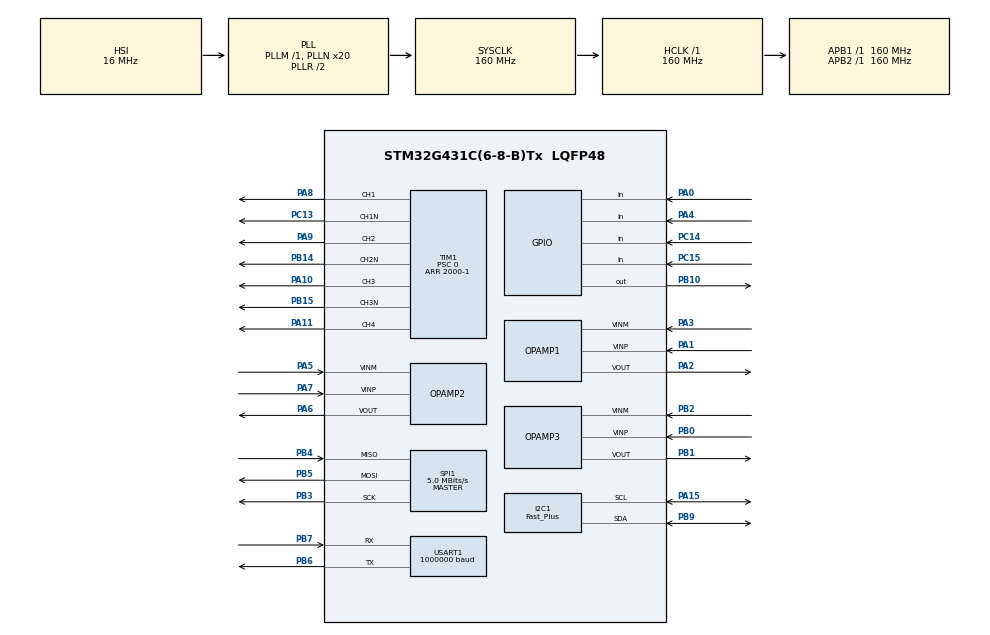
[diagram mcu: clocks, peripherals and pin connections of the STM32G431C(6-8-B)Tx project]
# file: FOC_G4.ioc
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ADC1.ContinuousConvMode=ENABLE
ADC1.DataAlign=ADC_DATAALIGN_RIGHT
ADC1.EOCSelection=ADC_EOC_SINGLE_CONV
ADC1.EnableAnalogWatchDog1=false
ADC1.EnableInjectedConversion=ENABLE
ADC1.EnableInjectedOversampling=DISABLE
ADC1.EnableRegularConversion=DISABLE
ADC1.ExternalTrigInjecConv=ADC_EXTERNALTRIGINJEC_T1_CC4
ADC1.ExternalTrigInjecConvEdge=ADC_EXTERNALTRIGINJECCONV_EDGE_FALLING
ADC1.InjNumberOfConversion=2
ADC1.InjectedChannel-11\#ChannelInjectedConversion=ADC_CHANNEL_3
ADC1.InjectedChannel-5\#ChannelInjectedConversion=ADC_CHANNEL_12
ADC1.InjectedConvMode=None
ADC1.InjectedOffsetNumber-11\#ChannelInjectedConversion=ADC_OFFSET_NONE
ADC1.InjectedOffsetNumber-5\#ChannelInjectedConversion=ADC_OFFSET_NONE
ADC1.InjectedOffsetSaturation-5\#ChannelInjectedConversion=DISABLE
ADC1.InjectedOffsetSign-5\#ChannelInjectedConversion=ADC_OFFSET_SIGN_POSITIVE
ADC1.InjectedRank-11\#ChannelInjectedConversion=2
ADC1.InjectedRank-5\#ChannelInjectedConversion=1
ADC1.InjectedSamplingTime-11\#ChannelInjectedConversion=ADC_SAMPLETIME_2CYCLES_5
ADC1.InjectedSamplingTime-5\#ChannelInjectedConversion=ADC_SAMPLETIME_2CYCLES_5
ADC1.Mode=ADC_MODE_INDEPENDENT
ADC1.Overrun=ADC_OVR_DATA_PRESERVED
ADC1.Rank2_Channel=ADC_CHANNEL_3
ADC1.Resolution=ADC_RESOLUTION_12B
ADC1.injectedQueueMode=DISABLE
ADC1.master=1
ADC2.ContinuousConvMode=ENABLE
ADC2.EOCSelection=ADC_EOC_SINGLE_CONV
ADC2.EnableInjectedConversion=ENABLE
ADC2.EnableInjectedOversampling=DISABLE
ADC2.EnableRegularConversion=DISABLE
ADC2.ExternalTrigInjecConv=ADC_EXTERNALTRIGINJEC_T1_CC4
ADC2.ExternalTrigInjecConvEdge=ADC_EXTERNALTRIGINJECCONV_EDGE_FALLING
ADC2.InjNumberOfConversion=1
ADC2.InjectedChannel-11\#ChannelInjectedConversion=ADC_CHANNEL_3
ADC2.InjectedConvMode=None
ADC2.InjectedOffsetNumber-11\#ChannelInjectedConversion=ADC_OFFSET_NONE
ADC2.InjectedRank-11\#ChannelInjectedConversion=1
ADC2.InjectedSamplingTime-11\#ChannelInjectedConversion=ADC_SAMPLETIME_2CYCLES_5
ADC2.injectedQueueMode=DISABLE
Dma.Request0=USART1_RX
Dma.Request1=USART1_TX
Dma.USART1_RX.0.Direction=DMA_PERIPH_TO_MEMORY
Dma.USART1_RX.0.EventEnable=DISABLE
Dma.USART1_RX.0.Instance=DMA2_Channel6
Dma.USART1_RX.0.MemDataAlignment=DMA_MDATAALIGN_BYTE
Dma.USART1_RX.0.MemInc=DMA_MINC_ENABLE
Dma.USART1_RX.0.Mode=DMA_NORMAL
Dma.USART1_RX.0.PeriphDataAlignment=DMA_PDATAALIGN_BYTE
Dma.USART1_RX.0.PeriphInc=DMA_PINC_DISABLE
Dma.USART1_RX.0.Polarity=HAL_DMAMUX_REQ_GEN_RISING
Dma.USART1_RX.0.Priority=DMA_PRIORITY_MEDIUM
Dma.USART1_RX.0.RequestNumber=1
Dma.USART1_RX.0.SignalID=NONE
Dma.USART1_RX.0.SyncEnable=DISABLE
Dma.USART1_RX.0.SyncPolarity=HAL_DMAMUX_SYNC_NO_EVENT
Dma.USART1_RX.0.SyncRequestNumber=1
Dma.USART1_RX.0.SyncSignalID=NONE
Dma.USART1_TX.1.Direction=DMA_MEMORY_TO_PERIPH
Dma.USART1_TX.1.EventEnable=DISABLE
Dma.USART1_TX.1.Instance=DMA1_Channel4
Dma.USART1_TX.1.MemDataAlignment=DMA_MDATAALIGN_BYTE
Dma.USART1_TX.1.MemInc=DMA_MINC_ENABLE
Dma.USART1_TX.1.Mode=DMA_NORMAL
Dma.USART1_TX.1.PeriphDataAlignment=DMA_PDATAALIGN_BYTE
Dma.USART1_TX.1.PeriphInc=DMA_PINC_DISABLE
Dma.USART1_TX.1.Polarity=HAL_DMAMUX_REQ_GEN_RISING
Dma.USART1_TX.1.Priority=DMA_PRIORITY_MEDIUM
Dma.USART1_TX.1.RequestNumber=1
Dma.USART1_TX.1.SignalID=NONE
Dma.USART1_TX.1.SyncEnable=DISABLE
Dma.USART1_TX.1.SyncPolarity=HAL_DMAMUX_SYNC_NO_EVENT
Dma.USART1_TX.1.SyncRequestNumber=1
Dma.USART1_TX.1.SyncSignalID=NONE
I2C1.Analog_Filter=I2C_ANALOGFILTER_ENABLE
I2C1.CustomTiming=Disabled
I2C1.I2C_Fall_Time=50
I2C1.I2C_Rise_Time=50
I2C1.I2C_Speed_Mode=I2C_Fast_Plus
I2C1.Timing=0x00F01F5B
Mcu.Family=STM32G4
Mcu.Name=STM32G431C(6-8-B)Tx
Mcu.Package=LQFP48
NVIC.ADC1_2_IRQn=true\:0\:0\:true\:false\:true\:false\:true\:true\:true
NVIC.DMA1_Channel4_IRQn=true\:0\:0\:false\:false\:true\:false\:true\:true\:true
NVIC.DMA2_Channel6_IRQn=true\:0\:0\:false\:false\:true\:false\:true\:true\:true
NVIC.PriorityGroup=NVIC_PRIORITYGROUP_4
NVIC.TIM1_UP_TIM16_IRQn=true\:15\:0\:true\:false\:true\:false\:false\:true\:true
NVIC.TIM4_IRQn=true\:15\:0\:false\:false\:true\:false\:false\:true\:true
NVIC.TimeBase=TIM4_IRQn
NVIC.TimeBaseIP=TIM4
NVIC.USART1_IRQn=true\:1\:0\:true\:false\:true\:false\:true\:true\:true
OPAMP1.PowerMode=OPAMP_POWERMODE_NORMALSPEED
OPAMP2.PowerMode=OPAMP_POWERMODE_NORMALSPEED
OPAMP3.PowerMode=OPAMP_POWERMODE_NORMALSPEED
PA0.Signal=GPIO_Input
PA1.Mode=Standalone
PA1.Signal=OPAMP1_VINP
PA10.GPIO_PuPd=GPIO_PULLDOWN
PA10.GPIO_Speed=GPIO_SPEED_FREQ_VERY_HIGH
PA10.Signal=S_TIM1_CH3
PA11.Signal=S_TIM1_CH4
PA13.Mode=Serial_Wire
PA13.Signal=SYS_JTMS-SWDIO
PA14.Mode=Serial_Wire
PA14.Signal=SYS_JTCK-SWCLK
PA15.GPIO_Pu=GPIO_PULLUP
PA15.GPIO_Speed=GPIO_SPEED_FREQ_VERY_HIGH
PA15.Mode=I2C
PA15.Signal=I2C1_SCL
PA2.GPIO_Mode=GPIO_MODE_ANALOG
PA2.GPIO_PuPd=GPIO_NOPULL
PA2.Signal=SharedAnalog_PA2
PA3.Mode=Standalone
PA3.Signal=OPAMP1_VINM
PA4.Signal=GPIO_Input
PA5.Mode=Standalone
PA5.Signal=OPAMP2_VINM
PA6.GPIO_Mode=GPIO_MODE_ANALOG
PA6.Signal=SharedAnalog_PA6
PA7.Mode=Standalone
PA7.Signal=OPAMP2_VINP
PA8.GPIO_PuPd=GPIO_PULLDOWN
PA8.GPIO_Speed=GPIO_SPEED_FREQ_VERY_HIGH
PA8.Signal=S_TIM1_CH1
PA9.GPIO_PuPd=GPIO_PULLDOWN
PA9.GPIO_Speed=GPIO_SPEED_FREQ_VERY_HIGH
PA9.Signal=S_TIM1_CH2
PB0.Mode=Standalone
PB0.Signal=OPAMP3_VINP
PB1.GPIO_PuPd=GPIO_NOPULL
PB1.Signal=SharedAnalog_PB1
PB10.Signal=GPIO_Output
PB14.GPIO_PuPd=GPIO_PULLDOWN
PB14.GPIO_Speed=GPIO_SPEED_FREQ_VERY_HIGH
PB14.Mode=PWM Generation2 CH2 CH2N
PB14.Signal=TIM1_CH2N
PB15.GPIO_PuPd=GPIO_PULLDOWN
PB15.GPIO_Speed=GPIO_SPEED_FREQ_VERY_HIGH
PB15.Mode=PWM Generation3 CH3 CH3N
PB15.Signal=TIM1_CH3N
PB2.Mode=Standalone
PB2.Signal=OPAMP3_VINM
PB3.Mode=Full_Duplex_Master
PB3.Signal=SPI1_SCK
PB4.Mode=Full_Duplex_Master
PB4.Signal=SPI1_MISO
PB5.Mode=Full_Duplex_Master
PB5.Signal=SPI1_MOSI
PB6.Mode=Multiprocessor_communication
PB6.Signal=USART1_TX
PB7.Mode=Multiprocessor_communication
PB7.Signal=USART1_RX
PB9.GPIO_FM9=SYSCFG_FASTMODEPLUS_PB9
PB9.GPIO_Pu=GPIO_PULLUP
PB9.GPIO_Speed=GPIO_SPEED_FREQ_VERY_HIGH
PB9.Mode=I2C
PB9.Signal=I2C1_SDA
PC13.GPIO_PuPd=GPIO_PULLDOWN
PC13.GPIO_Speed=GPIO_SPEED_FREQ_LOW
PC13.Mode=PWM Generation1 CH1 CH1N
PC13.Signal=TIM1_CH1N
PC14-OSC32_IN.Signal=GPIO_Input
PC15-OSC32_OUT.Signal=GPIO_Input
PF0-OSC_IN.Mode=HSE-External-Oscillator
PF0-OSC_IN.Signal=RCC_OSC_IN
PF1-OSC_OUT.Mode=HSE-External-Oscillator
PF1-OSC_OUT.Signal=RCC_OSC_OUT
ProjectManager.HeapSize=0x200
ProjectManager.StackSize=0x400
ProjectManager.TargetToolchain=MDK-ARM V5.32
RCC.ADC12Freq_Value=160000000
RCC.AHBFreq_Value=160000000
RCC.APB1Freq_Value=160000000
RCC.APB1TimFreq_Value=160000000
RCC.APB2Freq_Value=160000000
RCC.APB2TimFreq_Value=160000000
RCC.CortexFreq_Value=160000000
RCC.EXTERNAL_CLOCK_VALUE=12288000
RCC.HCLKFreq_Value=160000000
RCC.HSE_VALUE=8000000
RCC.HSI48_VALUE=48000000
RCC.HSI_VALUE=16000000
RCC.LSE_VALUE=32768
RCC.PLLN=20
RCC.SYSCLKFreq_VALUE=160000000
RCC.SYSCLKSource=RCC_SYSCLKSOURCE_PLLCLK
RCC.USBFreq_Value=160000000
RCC.VCOOutputFreq_Value=320000000
RealThread.RT-Thread.3.1.3.RTAaThreadCcRTOSJjkernel=true
RealThread.RT-Thread.3.1.3.RT_MAIN_THREAD_STACK_SIZE=512
RealThread.RT-Thread.3.1.3.RT_TICK_PER_SECOND=10000
RealThread.RT-Thread.3.1.3.RT_USING_HEAP=1
RealThread.RT-Thread.3.1.3.RT_USING_MESSAGEQUEUE=1
SH.S_TIM1_CH1.0=TIM1_CH1,PWM Generation1 CH1 CH1N
SH.S_TIM1_CH2.0=TIM1_CH2,PWM Generation2 CH2 CH2N
SH.S_TIM1_CH3.0=TIM1_CH3,PWM Generation3 CH3 CH3N
SH.S_TIM1_CH4.0=TIM1_CH4,PWM Generation4 CH4
SH.SharedAnalog_PA2.0=OPAMP1_VOUT,Standalone
SH.SharedAnalog_PA2.1=ADC1_IN3,IN3-Single-Ended
SH.SharedAnalog_PA6.0=OPAMP2_VOUT,Standalone
SH.SharedAnalog_PA6.1=ADC2_IN3,IN3-Single-Ended
SH.SharedAnalog_PB1.0=OPAMP3_VOUT,Standalone
SH.SharedAnalog_PB1.1=ADC1_IN12,IN12-Single-Ended
SPI1.BaudRatePrescaler=SPI_BAUDRATEPRESCALER_32
SPI1.CalculateBaudRate=5.0 MBits/s
SPI1.Direction=SPI_DIRECTION_2LINES
SPI1.Mode=SPI_MODE_MASTER
SPI1.VirtualType=VM_MASTER
TIM1.AutoReloadPreload=TIM_AUTORELOAD_PRELOAD_ENABLE
TIM1.Channel-PWM\ Generation1\ CH1\ CH1N=TIM_CHANNEL_1
TIM1.Channel-PWM\ Generation2\ CH2\ CH2N=TIM_CHANNEL_2
TIM1.Channel-PWM\ Generation3\ CH3\ CH3N=TIM_CHANNEL_3
TIM1.Channel-PWM\ Generation4\ CH4=TIM_CHANNEL_4
TIM1.ClockDivision=TIM_CLOCKDIVISION_DIV1
TIM1.CounterMode=TIM_COUNTERMODE_CENTERALIGNED1
TIM1.Dithering=Disable
TIM1.OC4Preload_PWM=DISABLE
TIM1.OCFastMode_PWM-PWM\ Generation2\ CH2\ CH2N=TIM_OCFAST_DISABLE
TIM1.OCFastMode_PWM-PWM\ Generation3\ CH3\ CH3N=TIM_OCFAST_DISABLE
TIM1.OCIdleState_4=TIM_OCIDLESTATE_RESET
TIM1.OCMode_PWM-PWM\ Generation1\ CH1\ CH1N=TIM_OCMODE_PWM2
TIM1.OCMode_PWM-PWM\ Generation2\ CH2\ CH2N=TIM_OCMODE_PWM2
TIM1.OCMode_PWM-PWM\ Generation3\ CH3\ CH3N=TIM_OCMODE_PWM2
TIM1.OCMode_PWM-PWM\ Generation4\ CH4=TIM_OCMODE_PWM2
TIM1.OCPolarity_4=TIM_OCPOLARITY_HIGH
TIM1.PeriodNoDither=2000-1
TIM1.Prescaler=0
TIM1.PulseNoDither_1=0
TIM1.PulseNoDither_2=0
TIM1.PulseNoDither_3=0
TIM1.PulseNoDither_4=80
TIM1.RepetitionCounter=0
TIM1.TIM_MasterOutputTrigger=TIM_TRGO_OC4REF
TIM1.TIM_MasterOutputTrigger2=TIM_TRGO2_RESET
TIM1.TIM_MasterSlaveMode=TIM_MASTERSLAVEMODE_DISABLE
TIM7.PeriodNoDither=150-1
TIM7.Prescaler=160-1
USART1.BaudRate=1000000
USART1.VirtualMode-Multiprocessor_communication=VM_ASYNC
VP_CORDIC_VS_CORDIC.Mode=CORDIC_Activate
VP_RealThread.RT-Thread_VS_RTOSJjRTAaThread_3.1.3.Mode=RTOSJjRTAaThread
VP_SYS_VS_DBSignals.Mode=DisableDeadBatterySignals
VP_SYS_VS_tim4.Mode=TIM4
VP_TIM1_VS_ClockSourceINT.Mode=Internal
VP_TIM7_VS_ClockSourceINT.Mode=Enable_Timer
board=custom

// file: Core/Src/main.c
/* USER CODE BEGIN Header */
/**
  ******************************************************************************
  * @file           : main.c
  * @brief          : Main program body
  ******************************************************************************
  * @attention
  *
  * Copyright (c) 2024 STMicroelectronics.
  * All rights reserved.
  *
  * This software is licensed under terms that can be found in the LICENSE file
  * in the root directory of this software component.
  * If no LICENSE file comes with this software, it is provided AS-IS.
  *
  ******************************************************************************
  */
/* USER CODE END Header */
#include "main.h"

/* USER CODE BEGIN Includes */
#include "app.h"
/* USER CODE END Includes */

ADC_HandleTypeDef hadc1;
ADC_HandleTypeDef hadc2;

CORDIC_HandleTypeDef hcordic;

I2C_HandleTypeDef hi2c1;

OPAMP_HandleTypeDef hopamp1;
OPAMP_HandleTypeDef hopamp2;
OPAMP_HandleTypeDef hopamp3;

SPI_HandleTypeDef hspi1;

TIM_HandleTypeDef htim1;
TIM_HandleTypeDef htim7;

UART_HandleTypeDef huart1;
DMA_HandleTypeDef hdma_usart1_rx;
DMA_HandleTypeDef hdma_usart1_tx;

void SystemClock_Config(void);
static void MX_GPIO_Init(void);
static void MX_DMA_Init(void);
static void MX_ADC1_Init(void);
static void MX_OPAMP1_Init(void);
static void MX_OPAMP2_Init(void);
static void MX_OPAMP3_Init(void);
static void MX_TIM1_Init(void);
static void MX_I2C1_Init(void);
static void MX_SPI1_Init(void);
static void MX_USART1_UART_Init(void);
static void MX_TIM7_Init(void);
static void MX_ADC2_Init(void);
static void MX_CORDIC_Init(void);

int main(void)
{

  /* MCU Configuration--------------------------------------------------------*/

  /* Reset of all peripherals, Initializes the Flash interface and the Systick. */
  HAL_Init();

  /* Configure the system clock */
  SystemClock_Config();

  /* Initialize all configured peripherals */
  MX_GPIO_Init();
  MX_DMA_Init();
  MX_ADC1_Init();
  MX_OPAMP1_Init();
  MX_OPAMP2_Init();
  MX_OPAMP3_Init();
  MX_TIM1_Init();
  MX_I2C1_Init();
  MX_SPI1_Init();
  MX_USART1_UART_Init();
  MX_TIM7_Init();
  MX_ADC2_Init();
  MX_CORDIC_Init();
  /* USER CODE BEGIN 2 */

	App_main();

  /* USER CODE END 2 */

  /* Infinite loop */
  while (1)
  {

  }
}

void SystemClock_Config(void)
{
  RCC_OscInitTypeDef RCC_OscInitStruct = {0};
  RCC_ClkInitTypeDef RCC_ClkInitStruct = {0};

  /** Configure the main internal regulator output voltage
  */
  HAL_PWREx_ControlVoltageScaling(PWR_REGULATOR_VOLTAGE_SCALE1_BOOST);

  /** Initializes the RCC Oscillators according to the specified parameters
  * in the RCC_OscInitTypeDef structure.
  */
  RCC_OscInitStruct.OscillatorType = RCC_OSCILLATORTYPE_HSI;
  RCC_OscInitStruct.HSIState = RCC_HSI_ON;
  RCC_OscInitStruct.HSICalibrationValue = RCC_HSICALIBRATION_DEFAULT;
  RCC_OscInitStruct.PLL.PLLState = RCC_PLL_ON;
  RCC_OscInitStruct.PLL.PLLSource = RCC_PLLSOURCE_HSI;
  RCC_OscInitStruct.PLL.PLLM = RCC_PLLM_DIV1;
  RCC_OscInitStruct.PLL.PLLN = 20;
  RCC_OscInitStruct.PLL.PLLP = RCC_PLLP_DIV2;
  RCC_OscInitStruct.PLL.PLLQ = RCC_PLLQ_DIV2;
  RCC_OscInitStruct.PLL.PLLR = RCC_PLLR_DIV2;
  if (HAL_RCC_OscConfig(&RCC_OscInitStruct) != HAL_OK)
  {
    Error_Handler();
  }

  /** Initializes the CPU, AHB and APB buses clocks
  */
  RCC_ClkInitStruct.ClockType = RCC_CLOCKTYPE_HCLK|RCC_CLOCKTYPE_SYSCLK
                              |RCC_CLOCKTYPE_PCLK1|RCC_CLOCKTYPE_PCLK2;
  RCC_ClkInitStruct.SYSCLKSource = RCC_SYSCLKSOURCE_PLLCLK;
  RCC_ClkInitStruct.AHBCLKDivider = RCC_SYSCLK_DIV1;
  RCC_ClkInitStruct.APB1CLKDivider = RCC_HCLK_DIV1;
  RCC_ClkInitStruct.APB2CLKDivider = RCC_HCLK_DIV1;

  if (HAL_RCC_ClockConfig(&RCC_ClkInitStruct, FLASH_LATENCY_4) != HAL_OK)
  {
    Error_Handler();
  }
}

static void MX_ADC1_Init(void)
{

  ADC_MultiModeTypeDef multimode = {0};
  ADC_InjectionConfTypeDef sConfigInjected = {0};

  /** Common config
  */
  hadc1.Instance = ADC1;
  hadc1.Init.ClockPrescaler = ADC_CLOCK_SYNC_PCLK_DIV4;
  hadc1.Init.Resolution = ADC_RESOLUTION_12B;
  hadc1.Init.DataAlign = ADC_DATAALIGN_RIGHT;
  hadc1.Init.GainCompensation = 0;
  hadc1.Init.ScanConvMode = ADC_SCAN_ENABLE;
  hadc1.Init.EOCSelection = ADC_EOC_SINGLE_CONV;
  hadc1.Init.LowPowerAutoWait = DISABLE;
  hadc1.Init.ContinuousConvMode = ENABLE;
  hadc1.Init.NbrOfConversion = 1;
  hadc1.Init.DiscontinuousConvMode = DISABLE;
  hadc1.Init.DMAContinuousRequests = DISABLE;
  hadc1.Init.Overrun = ADC_OVR_DATA_PRESERVED;
  hadc1.Init.OversamplingMode = DISABLE;
  if (HAL_ADC_Init(&hadc1) != HAL_OK)
  {
    Error_Handler();
  }

  /** Configure the ADC multi-mode
  */
  multimode.Mode = ADC_MODE_INDEPENDENT;
  if (HAL_ADCEx_MultiModeConfigChannel(&hadc1, &multimode) != HAL_OK)
  {
    Error_Handler();
  }

  /** Configure Injected Channel
  */
  sConfigInjected.InjectedChannel = ADC_CHANNEL_12;
  sConfigInjected.InjectedRank = ADC_INJECTED_RANK_1;
  sConfigInjected.InjectedSamplingTime = ADC_SAMPLETIME_2CYCLES_5;
  sConfigInjected.InjectedSingleDiff = ADC_SINGLE_ENDED;
  sConfigInjected.InjectedOffsetNumber = ADC_OFFSET_NONE;
  sConfigInjected.InjectedOffset = 0;
  sConfigInjected.InjectedOffsetSign = ADC_OFFSET_SIGN_POSITIVE;
  sConfigInjected.InjectedOffsetSaturation = DISABLE;
  sConfigInjected.InjectedNbrOfConversion = 2;
  sConfigInjected.InjectedDiscontinuousConvMode = DISABLE;
  sConfigInjected.AutoInjectedConv = DISABLE;
  sConfigInjected.QueueInjectedContext = DISABLE;
  sConfigInjected.ExternalTrigInjecConv = ADC_EXTERNALTRIGINJEC_T1_CC4;
  sConfigInjected.ExternalTrigInjecConvEdge = ADC_EXTERNALTRIGINJECCONV_EDGE_FALLING;
  sConfigInjected.InjecOversamplingMode = DISABLE;
  if (HAL_ADCEx_InjectedConfigChannel(&hadc1, &sConfigInjected) != HAL_OK)
  {
    Error_Handler();
  }

  /** Configure Injected Channel
  */
  sConfigInjected.InjectedChannel = ADC_CHANNEL_3;
  sConfigInjected.InjectedRank = ADC_INJECTED_RANK_2;
  if (HAL_ADCEx_InjectedConfigChannel(&hadc1, &sConfigInjected) != HAL_OK)
  {
    Error_Handler();
  }

}

static void MX_ADC2_Init(void)
{

  ADC_InjectionConfTypeDef sConfigInjected = {0};

  /** Common config
  */
  hadc2.Instance = ADC2;
  hadc2.Init.ClockPrescaler = ADC_CLOCK_SYNC_PCLK_DIV4;
  hadc2.Init.Resolution = ADC_RESOLUTION_12B;
  hadc2.Init.DataAlign = ADC_DATAALIGN_RIGHT;
  hadc2.Init.GainCompensation = 0;
  hadc2.Init.ScanConvMode = ADC_SCAN_DISABLE;
  hadc2.Init.EOCSelection = ADC_EOC_SINGLE_CONV;
  hadc2.Init.LowPowerAutoWait = DISABLE;
  hadc2.Init.ContinuousConvMode = ENABLE;
  hadc2.Init.NbrOfConversion = 1;
  hadc2.Init.DiscontinuousConvMode = DISABLE;
  hadc2.Init.DMAContinuousRequests = DISABLE;
  hadc2.Init.Overrun = ADC_OVR_DATA_PRESERVED;
  hadc2.Init.OversamplingMode = DISABLE;
  if (HAL_ADC_Init(&hadc2) != HAL_OK)
  {
    Error_Handler();
  }

  /** Configure Injected Channel
  */
  sConfigInjected.InjectedChannel = ADC_CHANNEL_3;
  sConfigInjected.InjectedRank = ADC_INJECTED_RANK_1;
  sConfigInjected.InjectedSamplingTime = ADC_SAMPLETIME_2CYCLES_5;
  sConfigInjected.InjectedSingleDiff = ADC_SINGLE_ENDED;
  sConfigInjected.InjectedOffsetNumber = ADC_OFFSET_NONE;
  sConfigInjected.InjectedOffset = 0;
  sConfigInjected.InjectedNbrOfConversion = 1;
  sConfigInjected.InjectedDiscontinuousConvMode = DISABLE;
  sConfigInjected.AutoInjectedConv = DISABLE;
  sConfigInjected.QueueInjectedContext = DISABLE;
  sConfigInjected.ExternalTrigInjecConv = ADC_EXTERNALTRIGINJEC_T1_CC4;
  sConfigInjected.ExternalTrigInjecConvEdge = ADC_EXTERNALTRIGINJECCONV_EDGE_FALLING;
  sConfigInjected.InjecOversamplingMode = DISABLE;
  if (HAL_ADCEx_InjectedConfigChannel(&hadc2, &sConfigInjected) != HAL_OK)
  {
    Error_Handler();
  }

}

static void MX_CORDIC_Init(void)
{

  hcordic.Instance = CORDIC;
  if (HAL_CORDIC_Init(&hcordic) != HAL_OK)
  {
    Error_Handler();
  }

}

static void MX_I2C1_Init(void)
{

  hi2c1.Instance = I2C1;
  hi2c1.Init.Timing = 0x00F01F5B;
  hi2c1.Init.OwnAddress1 = 0;
  hi2c1.Init.AddressingMode = I2C_ADDRESSINGMODE_7BIT;
  hi2c1.Init.DualAddressMode = I2C_DUALADDRESS_DISABLE;
  hi2c1.Init.OwnAddress2 = 0;
  hi2c1.Init.OwnAddress2Masks = I2C_OA2_NOMASK;
  hi2c1.Init.GeneralCallMode = I2C_GENERALCALL_DISABLE;
  hi2c1.Init.NoStretchMode = I2C_NOSTRETCH_DISABLE;
  if (HAL_I2C_Init(&hi2c1) != HAL_OK)
  {
    Error_Handler();
  }

  /** Configure Analogue filter
  */
  if (HAL_I2CEx_ConfigAnalogFilter(&hi2c1, I2C_ANALOGFILTER_ENABLE) != HAL_OK)
  {
    Error_Handler();
  }

  /** Configure Digital filter
  */
  if (HAL_I2CEx_ConfigDigitalFilter(&hi2c1, 0) != HAL_OK)
  {
    Error_Handler();
  }

  /** I2C Fast mode Plus enable
  */
  HAL_I2CEx_EnableFastModePlus(I2C_FASTMODEPLUS_I2C1);

}

static void MX_OPAMP1_Init(void)
{

  hopamp1.Instance = OPAMP1;
  hopamp1.Init.PowerMode = OPAMP_POWERMODE_NORMALSPEED;
  hopamp1.Init.Mode = OPAMP_STANDALONE_MODE;
  hopamp1.Init.InvertingInput = OPAMP_INVERTINGINPUT_IO0;
  hopamp1.Init.NonInvertingInput = OPAMP_NONINVERTINGINPUT_IO0;
  hopamp1.Init.InternalOutput = DISABLE;
  hopamp1.Init.TimerControlledMuxmode = OPAMP_TIMERCONTROLLEDMUXMODE_DISABLE;
  hopamp1.Init.UserTrimming = OPAMP_TRIMMING_FACTORY;
  if (HAL_OPAMP_Init(&hopamp1) != HAL_OK)
  {
    Error_Handler();
  }
  /* USER CODE BEGIN OPAMP1_Init 2 */
	HAL_OPAMP_Start(&hopamp1);
  /* USER CODE END OPAMP1_Init 2 */

}

static void MX_OPAMP2_Init(void)
{

  hopamp2.Instance = OPAMP2;
  hopamp2.Init.PowerMode = OPAMP_POWERMODE_NORMALSPEED;
  hopamp2.Init.Mode = OPAMP_STANDALONE_MODE;
  hopamp2.Init.InvertingInput = OPAMP_INVERTINGINPUT_IO0;
  hopamp2.Init.NonInvertingInput = OPAMP_NONINVERTINGINPUT_IO0;
  hopamp2.Init.InternalOutput = DISABLE;
  hopamp2.Init.TimerControlledMuxmode = OPAMP_TIMERCONTROLLEDMUXMODE_DISABLE;
  hopamp2.Init.UserTrimming = OPAMP_TRIMMING_FACTORY;
  if (HAL_OPAMP_Init(&hopamp2) != HAL_OK)
  {
    Error_Handler();
  }
  /* USER CODE BEGIN OPAMP2_Init 2 */
HAL_OPAMP_Start(&hopamp2);
  /* USER CODE END OPAMP2_Init 2 */

}

static void MX_OPAMP3_Init(void)
{

  hopamp3.Instance = OPAMP3;
  hopamp3.Init.PowerMode = OPAMP_POWERMODE_NORMALSPEED;
  hopamp3.Init.Mode = OPAMP_STANDALONE_MODE;
  hopamp3.Init.InvertingInput = OPAMP_INVERTINGINPUT_IO0;
  hopamp3.Init.NonInvertingInput = OPAMP_NONINVERTINGINPUT_IO0;
  hopamp3.Init.InternalOutput = DISABLE;
  hopamp3.Init.TimerControlledMuxmode = OPAMP_TIMERCONTROLLEDMUXMODE_DISABLE;
  hopamp3.Init.UserTrimming = OPAMP_TRIMMING_FACTORY;
  if (HAL_OPAMP_Init(&hopamp3) != HAL_OK)
  {
    Error_Handler();
  }
  /* USER CODE BEGIN OPAMP3_Init 2 */
HAL_OPAMP_Start(&hopamp3);
  /* USER CODE END OPAMP3_Init 2 */

}

static void MX_SPI1_Init(void)
{

  /* SPI1 parameter configuration*/
  hspi1.Instance = SPI1;
  hspi1.Init.Mode = SPI_MODE_MASTER;
  hspi1.Init.Direction = SPI_DIRECTION_2LINES;
  hspi1.Init.DataSize = SPI_DATASIZE_4BIT;
  hspi1.Init.CLKPolarity = SPI_POLARITY_LOW;
  hspi1.Init.CLKPhase = SPI_PHASE_1EDGE;
  hspi1.Init.NSS = SPI_NSS_SOFT;
  hspi1.Init.BaudRatePrescaler = SPI_BAUDRATEPRESCALER_32;
  hspi1.Init.FirstBit = SPI_FIRSTBIT_MSB;
  hspi1.Init.TIMode = SPI_TIMODE_DISABLE;
  hspi1.Init.CRCCalculation = SPI_CRCCALCULATION_DISABLE;
  hspi1.Init.CRCPolynomial = 7;
  hspi1.Init.CRCLength = SPI_CRC_LENGTH_DATASIZE;
  hspi1.Init.NSSPMode = SPI_NSS_PULSE_ENABLE;
  if (HAL_SPI_Init(&hspi1) != HAL_OK)
  {
    Error_Handler();
  }

}

static void MX_TIM1_Init(void)
{

  TIM_ClockConfigTypeDef sClockSourceConfig = {0};
  TIM_MasterConfigTypeDef sMasterConfig = {0};
  TIM_OC_InitTypeDef sConfigOC = {0};
  TIM_BreakDeadTimeConfigTypeDef sBreakDeadTimeConfig = {0};

  htim1.Instance = TIM1;
  htim1.Init.Prescaler = 0;
  htim1.Init.CounterMode = TIM_COUNTERMODE_CENTERALIGNED1;
  htim1.Init.Period = 1999;
  htim1.Init.ClockDivision = TIM_CLOCKDIVISION_DIV1;
  htim1.Init.RepetitionCounter = 0;
  htim1.Init.AutoReloadPreload = TIM_AUTORELOAD_PRELOAD_ENABLE;
  if (HAL_TIM_Base_Init(&htim1) != HAL_OK)
  {
    Error_Handler();
  }
  sClockSourceConfig.ClockSource = TIM_CLOCKSOURCE_INTERNAL;
  if (HAL_TIM_ConfigClockSource(&htim1, &sClockSourceConfig) != HAL_OK)
  {
    Error_Handler();
  }
  if (HAL_TIM_PWM_Init(&htim1) != HAL_OK)
  {
    Error_Handler();
  }
  sMasterConfig.MasterOutputTrigger = TIM_TRGO_OC4REF;
  sMasterConfig.MasterOutputTrigger2 = TIM_TRGO2_RESET;
  sMasterConfig.MasterSlaveMode = TIM_MASTERSLAVEMODE_DISABLE;
  if (HAL_TIMEx_MasterConfigSynchronization(&htim1, &sMasterConfig) != HAL_OK)
  {
    Error_Handler();
  }
  sConfigOC.OCMode = TIM_OCMODE_PWM2;
  sConfigOC.Pulse = 0;
  sConfigOC.OCPolarity = TIM_OCPOLARITY_HIGH;
  sConfigOC.OCNPolarity = TIM_OCNPOLARITY_HIGH;
  sConfigOC.OCFastMode = TIM_OCFAST_DISABLE;
  sConfigOC.OCIdleState = TIM_OCIDLESTATE_RESET;
  sConfigOC.OCNIdleState = TIM_OCNIDLESTATE_RESET;
  if (HAL_TIM_PWM_ConfigChannel(&htim1, &sConfigOC, TIM_CHANNEL_1) != HAL_OK)
  {
    Error_Handler();
  }
  if (HAL_TIM_PWM_ConfigChannel(&htim1, &sConfigOC, TIM_CHANNEL_2) != HAL_OK)
  {
    Error_Handler();
  }
  if (HAL_TIM_PWM_ConfigChannel(&htim1, &sConfigOC, TIM_CHANNEL_3) != HAL_OK)
  {
    Error_Handler();
  }
  sConfigOC.Pulse = 80;
  if (HAL_TIM_PWM_ConfigChannel(&htim1, &sConfigOC, TIM_CHANNEL_4) != HAL_OK)
  {
    Error_Handler();
  }
  __HAL_TIM_DISABLE_OCxPRELOAD(&htim1, TIM_CHANNEL_4);
  sBreakDeadTimeConfig.OffStateRunMode = TIM_OSSR_DISABLE;
  sBreakDeadTimeConfig.OffStateIDLEMode = TIM_OSSI_DISABLE;
  sBreakDeadTimeConfig.LockLevel = TIM_LOCKLEVEL_OFF;
  sBreakDeadTimeConfig.DeadTime = 0;
  sBreakDeadTimeConfig.BreakState = TIM_BREAK_DISABLE;
  sBreakDeadTimeConfig.BreakPolarity = TIM_BREAKPOLARITY_HIGH;
  sBreakDeadTimeConfig.BreakFilter = 0;
  sBreakDeadTimeConfig.BreakAFMode = TIM_BREAK_AFMODE_INPUT;
  sBreakDeadTimeConfig.Break2State = TIM_BREAK2_DISABLE;
  sBreakDeadTimeConfig.Break2Polarity = TIM_BREAK2POLARITY_HIGH;
  sBreakDeadTimeConfig.Break2Filter = 0;
  sBreakDeadTimeConfig.Break2AFMode = TIM_BREAK_AFMODE_INPUT;
  sBreakDeadTimeConfig.AutomaticOutput = TIM_AUTOMATICOUTPUT_DISABLE;
  if (HAL_TIMEx_ConfigBreakDeadTime(&htim1, &sBreakDeadTimeConfig) != HAL_OK)
  {
    Error_Handler();
  }
  HAL_TIM_MspPostInit(&htim1);

}

static void MX_TIM7_Init(void)
{

  TIM_MasterConfigTypeDef sMasterConfig = {0};

  htim7.Instance = TIM7;
  htim7.Init.Prescaler = 160-1;
  htim7.Init.CounterMode = TIM_COUNTERMODE_UP;
  htim7.Init.Period = 149;
  htim7.Init.AutoReloadPreload = TIM_AUTORELOAD_PRELOAD_DISABLE;
  if (HAL_TIM_Base_Init(&htim7) != HAL_OK)
  {
    Error_Handler();
  }
  sMasterConfig.MasterOutputTrigger = TIM_TRGO_RESET;
  sMasterConfig.MasterSlaveMode = TIM_MASTERSLAVEMODE_DISABLE;
  if (HAL_TIMEx_MasterConfigSynchronization(&htim7, &sMasterConfig) != HAL_OK)
  {
    Error_Handler();
  }

}

static void MX_USART1_UART_Init(void)
{

  huart1.Instance = USART1;
  huart1.Init.BaudRate = 1000000;
  huart1.Init.WordLength = UART_WORDLENGTH_8B;
  huart1.Init.StopBits = UART_STOPBITS_1;
  huart1.Init.Parity = UART_PARITY_NONE;
  huart1.Init.Mode = UART_MODE_TX_RX;
  huart1.Init.HwFlowCtl = UART_HWCONTROL_NONE;
  huart1.Init.OverSampling = UART_OVERSAMPLING_16;
  huart1.Init.OneBitSampling = UART_ONE_BIT_SAMPLE_DISABLE;
  huart1.Init.ClockPrescaler = UART_PRESCALER_DIV1;
  huart1.AdvancedInit.AdvFeatureInit = UART_ADVFEATURE_NO_INIT;
  if (HAL_MultiProcessor_Init(&huart1, 0, UART_WAKEUPMETHOD_IDLELINE) != HAL_OK)
  {
    Error_Handler();
  }
  if (HAL_UARTEx_SetTxFifoThreshold(&huart1, UART_TXFIFO_THRESHOLD_1_8) != HAL_OK)
  {
    Error_Handler();
  }
  if (HAL_UARTEx_SetRxFifoThreshold(&huart1, UART_RXFIFO_THRESHOLD_1_8) != HAL_OK)
  {
    Error_Handler();
  }
  if (HAL_UARTEx_DisableFifoMode(&huart1) != HAL_OK)
  {
    Error_Handler();
  }

}

static void MX_DMA_Init(void)
{

  /* DMA controller clock enable */
  __HAL_RCC_DMAMUX1_CLK_ENABLE();
  __HAL_RCC_DMA2_CLK_ENABLE();
  __HAL_RCC_DMA1_CLK_ENABLE();

  /* DMA interrupt init */
  /* DMA1_Channel4_IRQn interrupt configuration */
  HAL_NVIC_SetPriority(DMA1_Channel4_IRQn, 0, 0);
  HAL_NVIC_EnableIRQ(DMA1_Channel4_IRQn);
  /* DMA2_Channel6_IRQn interrupt configuration */
  HAL_NVIC_SetPriority(DMA2_Channel6_IRQn, 0, 0);
  HAL_NVIC_EnableIRQ(DMA2_Channel6_IRQn);

}

static void MX_GPIO_Init(void)
{
  GPIO_InitTypeDef GPIO_InitStruct = {0};

  /* GPIO Ports Clock Enable */
  __HAL_RCC_GPIOC_CLK_ENABLE();
  __HAL_RCC_GPIOF_CLK_ENABLE();
  __HAL_RCC_GPIOA_CLK_ENABLE();
  __HAL_RCC_GPIOB_CLK_ENABLE();

  /*Configure GPIO pin Output Level */
  HAL_GPIO_WritePin(GPIOB, GPIO_PIN_10, GPIO_PIN_RESET);

  /*Configure GPIO pins : PC14 PC15 */
  GPIO_InitStruct.Pin = GPIO_PIN_14|GPIO_PIN_15;
  GPIO_InitStruct.Mode = GPIO_MODE_INPUT;
  GPIO_InitStruct.Pull = GPIO_NOPULL;
  HAL_GPIO_Init(GPIOC, &GPIO_InitStruct);

  /*Configure GPIO pins : PA0 PA4 */
  GPIO_InitStruct.Pin = GPIO_PIN_0|GPIO_PIN_4;
  GPIO_InitStruct.Mode = GPIO_MODE_INPUT;
  GPIO_InitStruct.Pull = GPIO_NOPULL;
  HAL_GPIO_Init(GPIOA, &GPIO_InitStruct);

  /*Configure GPIO pin : PB10 */
  GPIO_InitStruct.Pin = GPIO_PIN_10;
  GPIO_InitStruct.Mode = GPIO_MODE_OUTPUT_PP;
  GPIO_InitStruct.Pull = GPIO_NOPULL;
  GPIO_InitStruct.Speed = GPIO_SPEED_FREQ_LOW;
  HAL_GPIO_Init(GPIOB, &GPIO_InitStruct);

}

void HAL_TIM_PeriodElapsedCallback(TIM_HandleTypeDef *htim)
{
  if (htim->Instance == TIM4) {
    HAL_IncTick();
  }
  /* USER CODE BEGIN Callback 1 */
	else if(htim->Instance==TIM1)
	{

	}
  /* USER CODE END Callback 1 */
}

void Error_Handler(void)
{
  __disable_irq();
  while (1)
  {
  }
}
